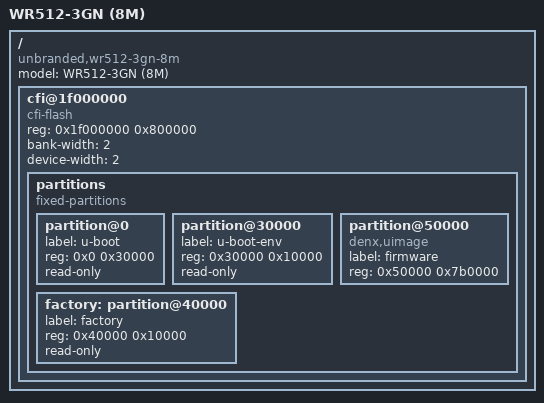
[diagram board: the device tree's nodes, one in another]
/dts-v1/;

#include "WR512-3GN.dtsi"

/ {
	compatible = "unbranded,wr512-3gn-8m", "unbranded,wr512-3gn", "ralink,rt3052-soc";
	model = "WR512-3GN (8M)";

	cfi@1f000000 {
		compatible = "cfi-flash";
		reg = <0x1f000000 0x800000>;
		bank-width = <2>;
		device-width = <2>;

		partitions {
			compatible = "fixed-partitions";
			#address-cells = <1>;
			#size-cells = <1>;

			partition@0 {
				label = "u-boot";
				reg = <0x0 0x30000>;
				read-only;
			};

			partition@30000 {
				label = "u-boot-env";
				reg = <0x30000 0x10000>;
				read-only;
			};

			factory: partition@40000 {
				label = "factory";
				reg = <0x40000 0x10000>;
				read-only;
			};

			partition@50000 {
				compatible = "denx,uimage";
				label = "firmware";
				reg = <0x50000 0x7b0000>;
			};
		};
	};
};
